# UPD70F3508 register map
Vendor: Renesas; Series: V850E2/Px4; File version: 1.0
CPU: other r0p0, little endian, no MPU, FPU, 4 interrupt priority bits
Registers are 8-bit, read-write, reset 0x0 unless marked. A register's access mark holds for its fields unless they carry their own. Offsets are from the block's base; [hi:lo] are bit positions; {n}, {i} and the like mark numbered series.

## JTAG_PORT0 — JTAG port 0 control registers (Table 2-8)
Base 0xFF440000
0x00 JP0 16-bit — JTAG port register (JP0_0 = TDI/TMS/TCK/TRST)
0x10 JPSR0 32-bit — JTAG port set / reset register
0x20 JPPR0 16-bit ro — JTAG port pin read register
0x30 JPM0 16-bit reset 0xFFFF — JTAG port mode register (0=output, 1=input)
0x70 JPNOT0 16-bit wo — JTAG port NOT register
0x80 JPMSR0 32-bit reset 0xFFFF — JTAG port mode set register
0x400 JPIBC0 16-bit — JTAG port input buffer control register
0x430 JPU0 16-bit — JTAG pull-up option register

## LVICNT — LVI Control Register (address cluster 0xFF450020) — part of POF/LVI functional block
Base 0xFF450020
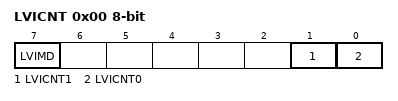
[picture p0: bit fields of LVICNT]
0x00 LVICNT — LVI Control Register — selects LVI output mode (reset vs interrupt) and enables voltage detection
  [7] LVIMD — LVI output mode: 0=output interrupt (INTLVI), 1=output reset (LVIRES)
  [1] LVICNT1 — LVI enable bit 1 (see Table 8-14 for device-specific detection voltage encoding)
  [0] LVICNT0 — LVI enable bit 0 (see Table 8-14 for device-specific detection voltage encoding)

## PBUS — Peripheral I/O Bus PSELG Error Detection and Control
Base 0xFF454000
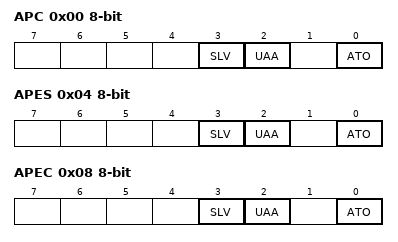
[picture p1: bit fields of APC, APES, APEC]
0x00 APC — Peripheral I/O Bus PSELG Control Register
  [3] SLV — Slave error EDC checking enable (not on µPD70F3508/3509)
  [2] UAA — Undefined-area-access checking enable (0=disabled, 1=enabled)
  [0] ATO — Access-timeout checking enable (0=disabled, 1=enabled)
0x04 APES ro — Peripheral I/O Bus PSELG Error Status Register
  [3] SLV — Slave error generated flag (not on µPD70F3508/3509)
  [2] UAA — Undefined-area-access error generated flag
  [0] ATO — Access-timeout error generated flag
0x08 APEC — Peripheral I/O Bus PSELG Error Status Clear Register
  [3] SLV — Clear APES.SLV slave-error source flag (not on µPD70F3508/3509)
  [2] UAA — Clear APES.UAA undefined-area-access error source flag
  [0] ATO — Clear APES.ATO access-timeout error source flag
0x0C APAM 32-bit ro reset 0xFF000000 — Peripheral I/O Bus PSELG Error Address Store Register
  [23:0] A — Address of most recent peripheral I/O bus access error [23:0]
0x10 MATS — Peripheral I/O Bus Maximum Access Time Set Register
  [3:0] MATS — Maximum bus access time selection (MATS[3:0]; 0000=2^9/PCLK through 0111=2^16/PCLK; others prohibited)

## ECC_CAN0 — CAN0 RAM ECC Control Registers (E6A0CTL, E6A1CTL)
Base 0xFF460000
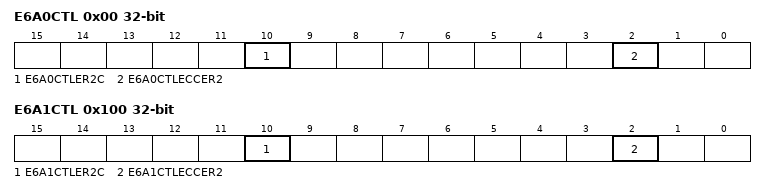
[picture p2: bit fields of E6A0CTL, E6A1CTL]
0x00 E6A0CTL 32-bit — CAN0 ECC0 Control Register — ECC error flag and clear for CAN0 RAM bank 0
  [10] E6A0CTLER2C — Clear E6A0CTL.E6A0CTLECCER2 (write 1 to clear; reads always 0)
  [2] E6A0CTLECCER2 — CAN0 RAM ECC error flag (0=no error, 1=ECC error generated)
0x100 E6A1CTL 32-bit — CAN0 ECC1 Control Register — ECC error flag and clear for CAN0 RAM bank 1
  [10] E6A1CTLER2C — Clear E6A1CTL.E6A1CTLECCER2 (write 1 to clear; reads always 0)
  [2] E6A1CTLECCER2 — CAN0 RAM ECC error flag bank 1 (0=no error, 1=ECC error generated)

## ECC_CAN1 — CAN1 RAM ECC Control Registers (E6A2CTL, E6A3CTL)
Base 0xFF460800
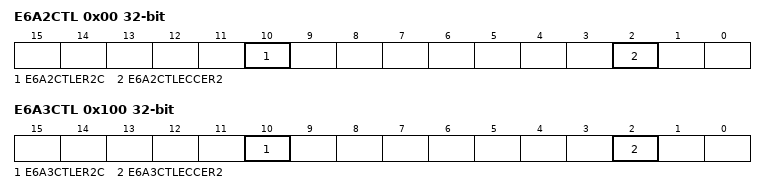
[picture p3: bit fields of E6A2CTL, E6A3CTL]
0x00 E6A2CTL 32-bit — CAN1 ECC0 Control Register — ECC error flag and clear for CAN1 RAM bank 0
  [10] E6A2CTLER2C — Clear E6A2CTL.E6A2CTLECCER2 (write 1 to clear; reads always 0)
  [2] E6A2CTLECCER2 — CAN1 RAM ECC error flag bank 0 (0=no error, 1=ECC error generated)
0x100 E6A3CTL 32-bit — CAN1 ECC1 Control Register — ECC error flag and clear for CAN1 RAM bank 1
  [10] E6A3CTLER2C — Clear E6A3CTL.E6A3CTLECCER2 (write 1 to clear; reads always 0)
  [2] E6A3CTLECCER2 — CAN1 RAM ECC error flag bank 1 (0=no error, 1=ECC error generated)

## ECC_FLEXRAY — FlexRay RAM ECC Control Registers (E7A0CTL to E7A6CTL; not on µPD70F3505A) (merged: ECC_FLEXRAY, ECC_FLX)
Base 0xFF464000
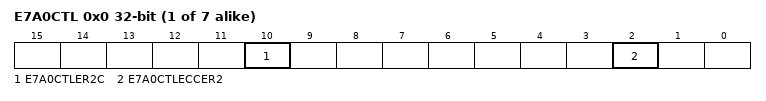
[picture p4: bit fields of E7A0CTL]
{0x0+0x100*i} E7A{i}CTL 32-bit (i=0..6) — FlexRay ECC{i} Control Register
  [10] E7A{i}CTLER2C — Clear E7A{i}CTL.E7A{i}CTLECCER2 (write 1 to clear; reads always 0)
  [2] E7A{i}CTLECCER2 — FlexRay RAM ECC error flag ch{i} (0=no error, 1=ECC error generated)
